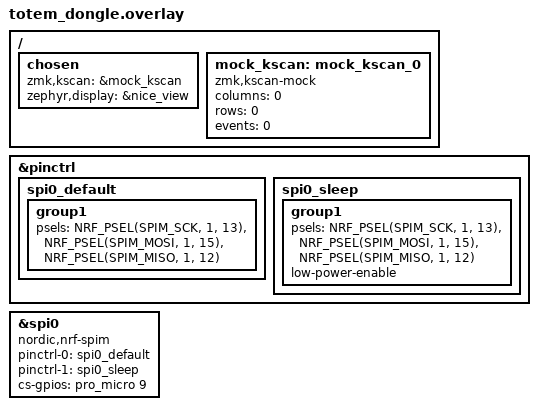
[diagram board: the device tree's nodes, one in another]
#include <dt-bindings/zmk/matrix_transform.h>

&pinctrl {
    spi0_default: spi0_default {
        group1 {
            psels = <NRF_PSEL(SPIM_SCK, 1, 13)>,
                <NRF_PSEL(SPIM_MOSI, 1, 15)>,
                <NRF_PSEL(SPIM_MISO, 1, 12)>;
        };
    };
    spi0_sleep: spi0_sleep {
        group1 {
            psels = <NRF_PSEL(SPIM_SCK, 1, 13)>,
                <NRF_PSEL(SPIM_MOSI, 1, 15)>,
                <NRF_PSEL(SPIM_MISO, 1, 12)>;
            low-power-enable;
        };
    };
};

nice_view_spi: &spi0 {
    compatible = "nordic,nrf-spim";
    pinctrl-0 = <&spi0_default>;
    pinctrl-1 = <&spi0_sleep>;
    pinctrl-names = "default", "sleep";
    cs-gpios = <&pro_micro 9 GPIO_ACTIVE_HIGH>;
};

/ {
    chosen {
        zmk,kscan = &mock_kscan;
        zephyr,display = &nice_view;
    };

    mock_kscan: mock_kscan_0 {
        compatible = "zmk,kscan-mock";
        columns = <0>;
        rows = <0>;
        events = <0>;
    };
};
